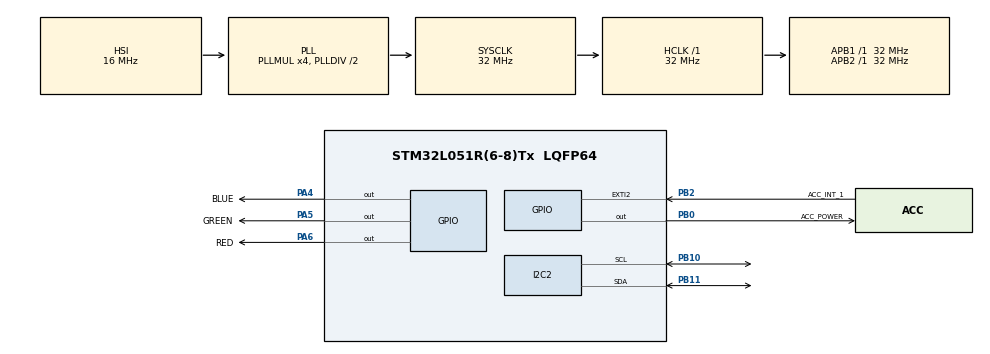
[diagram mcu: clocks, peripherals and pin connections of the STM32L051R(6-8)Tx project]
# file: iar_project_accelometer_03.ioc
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I2C2.NoStretchMode=I2C_NOSTRETCH_DISABLE
I2C2.Timing=0x00707CBB
Mcu.Family=STM32L0
Mcu.Name=STM32L051R(6-8)Tx
Mcu.Package=LQFP64
NVIC.EXTI2_3_IRQn=true\:0\:0\:false\:false\:true\:true\:true\:true
NVIC.RTC_IRQn=true\:0\:0\:false\:false\:true\:true\:true\:true
NVIC.TIM6_DAC_IRQn=true\:0\:0\:false\:false\:true\:true\:true\:true
PA13.Mode=Serial_Wire
PA13.Signal=SYS_SWDIO
PA14.Mode=Serial_Wire
PA14.Signal=SYS_SWCLK
PA4.GPIO_Label=BLUE
PA4.Signal=GPIO_Output
PA5.GPIO_Label=GREEN
PA5.Signal=GPIO_Output
PA6.GPIO_Label=RED
PA6.Signal=GPIO_Output
PB0.GPIO_Label=ACC_POWER
PB0.PinState=GPIO_PIN_SET
PB0.Signal=GPIO_Output
PB10.GPIO_Pu=GPIO_PULLUP
PB10.Mode=I2C
PB10.Signal=I2C2_SCL
PB11.GPIO_Pu=GPIO_PULLUP
PB11.Mode=I2C
PB11.Signal=I2C2_SDA
PB2.GPIO_Label=ACC_INT_1
PB2.Signal=GPXTI2
ProjectManager.HeapSize=0x200
ProjectManager.StackSize=0x400
ProjectManager.TargetToolchain=EWARM V8.32
RCC.AHBFreq_Value=32000000
RCC.APB1Freq_Value=32000000
RCC.APB1TimFreq_Value=32000000
RCC.APB2Freq_Value=32000000
RCC.APB2TimFreq_Value=32000000
RCC.HCLKFreq_Value=32000000
RCC.HSE_VALUE=8000000
RCC.HSI16_VALUE=16000000
RCC.HSI_VALUE=16000000
RCC.MSI_VALUE=2097000
RCC.PLLMUL=RCC_PLLMUL_4
RCC.SYSCLKFreq_VALUE=32000000
RCC.SYSCLKSource=RCC_SYSCLKSOURCE_PLLCLK
RCC.VCOOutputFreq_Value=64000000
RTC.SynchPrediv=288
RTC.WakeUpClock-WakeUp=RTC_WAKEUPCLOCK_CK_SPRE_16BITS
RTC.WakeUpCounter-WakeUp=10
TIM2.Period=0xffff
TIM2.Prescaler=31
TIM6.Period=999
TIM6.Prescaler=32
VP_RTC_VS_RTC_Activate.Mode=RTC_Enabled
VP_RTC_VS_RTC_Calendar.Mode=RTC_Calendar
VP_RTC_VS_RTC_WakeUp_intern.Mode=WakeUp
VP_TIM2_VS_ClockSourceINT.Mode=Internal
VP_TIM6_VS_ClockSourceINT.Mode=Enable_Timer
board=custom

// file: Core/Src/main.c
/* USER CODE BEGIN Header */
/**
  ******************************************************************************
  * @file           : main.c
  * @brief          : Main program body
  ******************************************************************************
  * @attention
  *
  * Copyright (c) 2023 STMicroelectronics.
  * All rights reserved.
  *
  * This software is licensed under terms that can be found in the LICENSE file
  * in the root directory of this software component.
  * If no LICENSE file comes with this software, it is provided AS-IS.
  *
  ******************************************************************************
  */
/* USER CODE END Header */
#include "main.h"
#include "i2c.h"
#include "rtc.h"
#include "tim.h"
#include "gpio.h"

/* USER CODE BEGIN Includes */
#include "usr_general.h"
/* USER CODE END Includes */

void SystemClock_Config(void);

int main(void)
{

  /* MCU Configuration--------------------------------------------------------*/

  /* Reset of all peripherals, Initializes the Flash interface and the Systick. */
  HAL_Init();

  /* Configure the system clock */
  SystemClock_Config();

  /* Initialize all configured peripherals */
  MX_GPIO_Init();
  MX_I2C2_Init();
  MX_TIM2_Init();
  MX_TIM6_Init();
  MX_RTC_Init();
  /* USER CODE BEGIN 2 */
  //HAL_GPIO_WritePin(RED_GPIO_Port, RED_Pin, GPIO_PIN_SET);        // Rgb led red pwm pin
  //HAL_GPIO_WritePin(GREEN_GPIO_Port, GREEN_Pin, GPIO_PIN_SET);    // Rgb led green pwm
  //HAL_GPIO_WritePin(BLUE_GPIO_Port, BLUE_Pin, GPIO_PIN_SET);      // Rgb led blue pwm

  UsrSystemInitial();
  /* USER CODE END 2 */

  /* Infinite loop */
  while (1)
  {

    /* USER CODE BEGIN 3 */
    UsrSystemGeneral();
  }
  /* USER CODE END 3 */
}

void SystemClock_Config(void)
{
  RCC_OscInitTypeDef RCC_OscInitStruct = {0};
  RCC_ClkInitTypeDef RCC_ClkInitStruct = {0};
  RCC_PeriphCLKInitTypeDef PeriphClkInit = {0};

  /** Configure the main internal regulator output voltage
  */
  __HAL_PWR_VOLTAGESCALING_CONFIG(PWR_REGULATOR_VOLTAGE_SCALE1);

  /** Initializes the RCC Oscillators according to the specified parameters
  * in the RCC_OscInitTypeDef structure.
  */
  RCC_OscInitStruct.OscillatorType = RCC_OSCILLATORTYPE_HSI|RCC_OSCILLATORTYPE_LSI;
  RCC_OscInitStruct.HSIState = RCC_HSI_ON;
  RCC_OscInitStruct.HSICalibrationValue = RCC_HSICALIBRATION_DEFAULT;
  RCC_OscInitStruct.LSIState = RCC_LSI_ON;
  RCC_OscInitStruct.PLL.PLLState = RCC_PLL_ON;
  RCC_OscInitStruct.PLL.PLLSource = RCC_PLLSOURCE_HSI;
  RCC_OscInitStruct.PLL.PLLMUL = RCC_PLLMUL_4;
  RCC_OscInitStruct.PLL.PLLDIV = RCC_PLLDIV_2;
  if (HAL_RCC_OscConfig(&RCC_OscInitStruct) != HAL_OK)
  {
    Error_Handler();
  }

  /** Initializes the CPU, AHB and APB buses clocks
  */
  RCC_ClkInitStruct.ClockType = RCC_CLOCKTYPE_HCLK|RCC_CLOCKTYPE_SYSCLK
                              |RCC_CLOCKTYPE_PCLK1|RCC_CLOCKTYPE_PCLK2;
  RCC_ClkInitStruct.SYSCLKSource = RCC_SYSCLKSOURCE_PLLCLK;
  RCC_ClkInitStruct.AHBCLKDivider = RCC_SYSCLK_DIV1;
  RCC_ClkInitStruct.APB1CLKDivider = RCC_HCLK_DIV1;
  RCC_ClkInitStruct.APB2CLKDivider = RCC_HCLK_DIV1;

  if (HAL_RCC_ClockConfig(&RCC_ClkInitStruct, FLASH_LATENCY_1) != HAL_OK)
  {
    Error_Handler();
  }
  PeriphClkInit.PeriphClockSelection = RCC_PERIPHCLK_RTC;
  PeriphClkInit.RTCClockSelection = RCC_RTCCLKSOURCE_LSI;
  if (HAL_RCCEx_PeriphCLKConfig(&PeriphClkInit) != HAL_OK)
  {
    Error_Handler();
  }
}

void Error_Handler(void)
{
  __disable_irq();
  while (1)
  {
  }
}
